# LPC54018M register map
Vendor: nxp.com; File version: 1.0
CPU: CM4 r0p1, little endian, MPU, FPU, VTOR, 3 interrupt priority bits
Registers are 32-bit, read-write, reset 0x0 unless marked. A register's access mark holds for its fields unless they carry their own. Offsets are from the block's base; [hi:lo] are bit positions; {n}, {i} and the like mark numbered series; 'fields as' and 'values as' point back to an identical list.

## ASYNC_SYSCON — LPC5411x Asynchronous system configuration (ASYNC_SYSCON)
Base 0x40040000
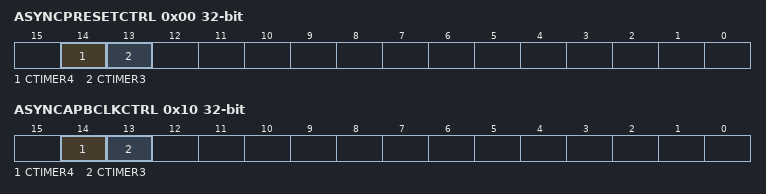
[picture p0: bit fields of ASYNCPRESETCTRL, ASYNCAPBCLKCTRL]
0x00 ASYNCPRESETCTRL — Async peripheral reset control
  [14] CTIMER4 — Standard counter/timer CTIMER4 reset control. 0 = Clear reset to this function. 1 = Assert reset to this function.
  [13] CTIMER3 — Standard counter/timer CTIMER3 reset control. 0 = Clear reset to this function. 1 = Assert reset to this function.
0x04 ASYNCPRESETCTRLSET wo reset not defined — Set bits in ASYNCPRESETCTRL
  [31:0] ARST_SET — Writing ones to this register sets the corresponding bit or bits in the ASYNCPRESETCTRL register, if they are implemented. Bits that do not correspond to defined bits in ASYNCPRESETCTRL are reserved and only zeroes should be written to them.
0x08 ASYNCPRESETCTRLCLR wo reset not defined — Clear bits in ASYNCPRESETCTRL
  [31:0] ARST_CLR — Writing ones to this register clears the corresponding bit or bits in the ASYNCPRESETCTRL register, if they are implemented. Bits that do not correspond to defined bits in ASYNCPRESETCTRL are reserved and only zeroes should be written to them.
0x10 ASYNCAPBCLKCTRL — Async peripheral clock control
  [14] CTIMER4 — Controls the clock for CTIMER4. 0 = Disable; 1 = Enable.
  [13] CTIMER3 — Controls the clock for CTIMER3. 0 = Disable; 1 = Enable.
0x14 ASYNCAPBCLKCTRLSET wo reset not defined — Set bits in ASYNCAPBCLKCTRL
  [31:0] ACLK_SET — Writing ones to this register sets the corresponding bit or bits in the ASYNCAPBCLKCTRL register, if they are implemented. Bits that do not correspond to defined bits in ASYNCPRESETCTRL are reserved and only zeroes should be written to them.
0x18 ASYNCAPBCLKCTRLCLR wo reset not defined — Clear bits in ASYNCAPBCLKCTRL
  [31:0] ACLK_CLR — Writing ones to this register clears the corresponding bit or bits in the ASYNCAPBCLKCTRL register, if they are implemented. Bits that do not correspond to defined bits in ASYNCAPBCLKCTRL are reserved and only zeroes should be written to them.
0x20 ASYNCAPBCLKSELA — Async APB clock source select A
  [1:0] SEL — Clock source for asynchronous clock source selector A
    0=MAIN_CLOCK (Main clock (main_clk)); 1=FRO_12_MHZ (FRO 12 MHz (fro_12m)); 2=AUDIO_PLL_CLOCK (Audio PLL clock.(AUDPLL_BYPASS)); 3=FC6_FCLK (fc6 fclk (fc6_fclk))

## FLEXCOMM0 — LPC5400x Flexcomm serial communication
Base 0x40086000
Same registers: FLEXCOMM1 0x40087000, FLEXCOMM2 0x40088000, FLEXCOMM3 0x40089000, FLEXCOMM4 0x4008A000, FLEXCOMM5 0x40096000, FLEXCOMM6 0x40097000, FLEXCOMM7 0x40098000, FLEXCOMM8 0x40099000, FLEXCOMM9 0x4009A000, FLEXCOMM10 0x4009F000
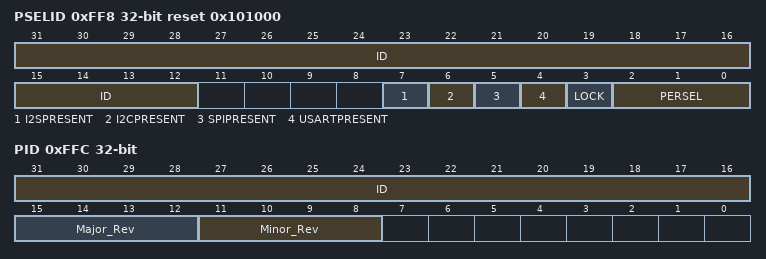
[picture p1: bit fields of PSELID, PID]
0xFF8 PSELID reset 0x101000 — Peripheral Select and Flexcomm ID register.
  [31:12] ID ro — Flexcomm ID.
  [7] I2SPRESENT ro — I 2S present indicator. This field is Read-only.
    0=NOT_PRESENT (This Flexcomm does not include the I2S function.); 1=PRESENT (This Flexcomm includes the I2S function.)
  [6] I2CPRESENT ro — I2C present indicator. This field is Read-only.
    0=NOT_PRESENT (This Flexcomm does not include the I2C function.); 1=PRESENT (This Flexcomm includes the I2C function.)
  [5] SPIPRESENT ro — SPI present indicator. This field is Read-only.
    0=NOT_PRESENT (This Flexcomm does not include the SPI function.); 1=PRESENT (This Flexcomm includes the SPI function.)
  [4] USARTPRESENT ro — USART present indicator. This field is Read-only.
    0=NOT_PRESENT (This Flexcomm does not include the USART function.); 1=PRESENT (This Flexcomm includes the USART function.)
  [3] LOCK — Lock the peripheral select. This field is writable by software.
    0=UNLOCKED (Peripheral select can be changed by software.); 1=LOCKED (Peripheral select is locked and cannot be changed until this Flexcomm or the entire device is reset.)
  [2:0] PERSEL — Peripheral Select. This field is writable by software.
    0=NO_PERIPH_SELECTED (No peripheral selected.); 1=USART (USART function selected.); 2=SPI (SPI function selected.); 3=I2C (I2C function selected.); 4=I2S_TRANSMIT (I2S transmit function selected.); 5=I2S_RECEIVE (I2S receive function selected.)
0xFFC PID — Peripheral identification register.
  [31:16] ID ro — Module identifier for the selected function.
  [15:12] Major_Rev ro — Major revision of module implementation.
  [11:8] Minor_Rev ro — Minor revision of module implementation.

## CRC_ENGINE — LPC5411x CRC engine
Base 0x40095000
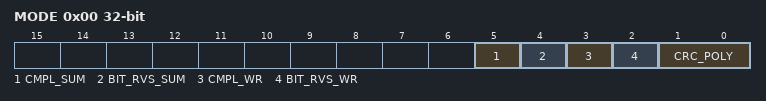
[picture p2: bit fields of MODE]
0x00 MODE — CRC mode register
  [5] CMPL_SUM — CRC sum complement: 1 = 1's complement for CRC_SUM 0 = No 1's complement for CRC_SUM
  [4] BIT_RVS_SUM — CRC sum bit order: 1 = Bit order reverse for CRC_SUM 0 = No bit order reverse for CRC_SUM
  [3] CMPL_WR — Data complement: 1 = 1's complement for CRC_WR_DATA 0 = No 1's complement for CRC_WR_DATA
  [2] BIT_RVS_WR — Data bit order: 1 = Bit order reverse for CRC_WR_DATA (per byte) 0 = No bit order reverse for CRC_WR_DATA (per byte)
  [1:0] CRC_POLY — CRC polynomial: 1X = CRC-32 polynomial 01 = CRC-16 polynomial 00 = CRC-CCITT polynomial
0x04 SEED reset 0xFFFF — CRC seed register
  [31:0] CRC_SEED — A write access to this register will load CRC seed value to CRC_SUM register with selected bit order and 1's complement pre-processes. A write access to this register will overrule the CRC calculation in progresses.
0x08 SUM ro reset 0xFFFF (SUM_WR_DATA view) — CRC checksum register
  [31:0] CRC_SUM — The most recent CRC sum can be read through this register with selected bit order and 1's complement post-processes.
0x08 WR_DATA wo (SUM_WR_DATA view) — CRC data register
  [31:0] CRC_WR_DATA — Data written to this register will be taken to perform CRC calculation with selected bit order and 1's complement pre-process. Any write size 8, 16 or 32-bit are allowed and accept back-to-back transactions.

## SHA0 — SHA
Base 0x400A4000
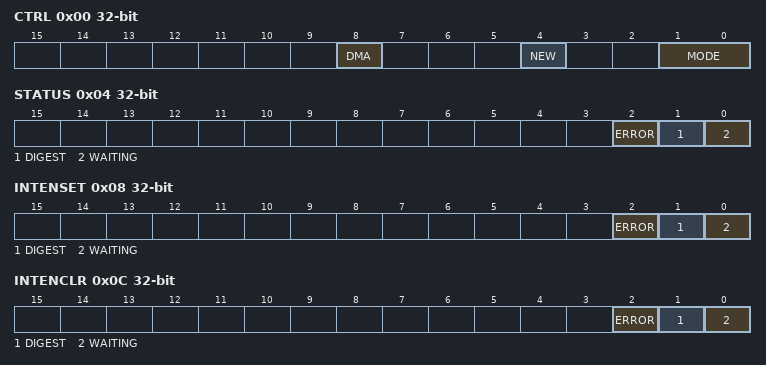
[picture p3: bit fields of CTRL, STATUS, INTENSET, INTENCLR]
0x00 CTRL — Control register
  [8] DMA — When this bit is set, the DMA is used to fill INDATA.
  [4] NEW — When this bit is set, a new hash operation is started.
  [1:0] MODE — This field is used to select the operational mode of SHA block.
0x04 STATUS
  [2] ERROR — This field indicates if an error has occurred.
  [1] DIGEST — This field indicates if a DIGEST is ready and waiting and there is no active next block that has already started.
  [0] WAITING — This field indicates if the block is waiting for more data to process.
0x08 INTENSET — Interrupt Enable register
  [2] ERROR — This field indicates if interrupt is generated on an ERROR (as defined in STAT register).
  [1] DIGEST — This field indicates if interrupt is generated when Digest is ready (completed a Hash or completed a full sequence).
  [0] WAITING — This field indicates if interrupt should be enabled when waiting for input data.
0x0C INTENCLR wo — Interrupt Clear register
  [2] ERROR — Writing a 1 clears the interrupt enabled by the INTENSET register.
  [1] DIGEST — Writing a 1 clears the interrupt enabled by the INTENSET register.
  [0] WAITING — Writing a 1 clears the interrupt enabled by the INTENSET register.
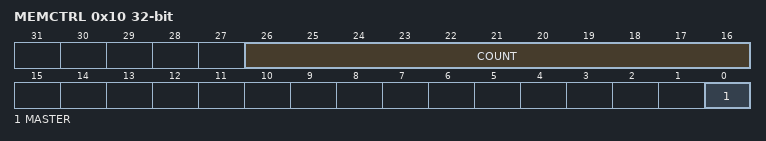
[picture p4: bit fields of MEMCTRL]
0x10 MEMCTRL — Memory Control register
  [26:16] COUNT — This field indicates the number of 512-bit blocks to copy starting at MEMADDR.
  [0] MASTER — This field is used to enable SHA block as AHB bus master.
0x14 MEMADDR — Memory Address register
  [31:0] BASEADDR — This field indicates the base address in Internal Flash, SRAM0, SRAMX, or SPIFI to start copying from.
0x20 INDATA wo — Input Data register
  [31:0] DATA — In this field the next word is written in little-endian format.
{0x24+4i} ALIAS[{i}] (i=0..6) wo
  fields as INDATA
{0x40+4i} DIGEST[{i}] (i=0..7) ro
  [31:0] DIGEST — This field contains one word of the Digest.

## Notices in the file
Copyright 2016-2018 NXP
All rights reserved.
SPDX-License-Identifier: BSD-3-Clause
